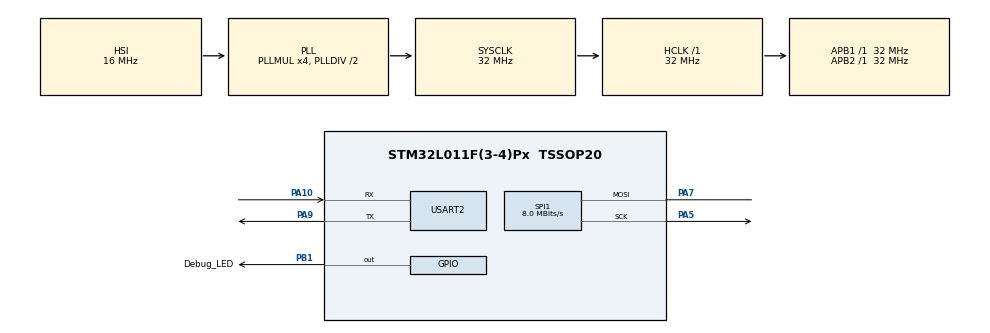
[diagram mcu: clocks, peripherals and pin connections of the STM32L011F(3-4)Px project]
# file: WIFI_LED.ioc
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Dma.Request0=SPI1_TX
Dma.SPI1_TX.0.Direction=DMA_MEMORY_TO_PERIPH
Dma.SPI1_TX.0.Instance=DMA1_Channel5
Dma.SPI1_TX.0.MemDataAlignment=DMA_MDATAALIGN_HALFWORD
Dma.SPI1_TX.0.MemInc=DMA_MINC_ENABLE
Dma.SPI1_TX.0.Mode=DMA_NORMAL
Dma.SPI1_TX.0.PeriphDataAlignment=DMA_PDATAALIGN_HALFWORD
Dma.SPI1_TX.0.PeriphInc=DMA_PINC_DISABLE
Dma.SPI1_TX.0.Priority=DMA_PRIORITY_HIGH
Mcu.Family=STM32L0
Mcu.Name=STM32L011F(3-4)Px
Mcu.Package=TSSOP20
NVIC.DMA1_Channel4_5_IRQn=true\:0\:0\:false\:false\:true\:false\:true
NVIC.USART2_IRQn=true\:0\:0\:false\:false\:true\:true\:true
PA10.Mode=Asynchronous
PA10.Signal=USART2_RX
PA13.Mode=Serial_Wire
PA13.Signal=SYS_SWDIO
PA14.Mode=Serial_Wire
PA14.Signal=SYS_SWCLK
PA5.Mode=Simplex_Bidirectional_Master
PA5.Signal=SPI1_SCK
PA7.Mode=Simplex_Bidirectional_Master
PA7.Signal=SPI1_MOSI
PA9.Mode=Asynchronous
PA9.Signal=USART2_TX
PB1.GPIO_Label=Debug_LED
PB1.GPIO_ModeDefaultOutputPP=GPIO_MODE_OUTPUT_PP
PB1.GPIO_PuPd=GPIO_PULLUP
PB1.GPIO_Speed=GPIO_SPEED_FREQ_LOW
PB1.PinState=GPIO_PIN_SET
PB1.Signal=GPIO_Output
PC14-OSC32_IN.Mode=LSE-External-Oscillator
PC14-OSC32_IN.Signal=RCC_OSC32_IN
PC15-OSC32_OUT.Mode=LSE-External-Oscillator
PC15-OSC32_OUT.Signal=RCC_OSC32_OUT
ProjectManager.HeapSize=0x200
ProjectManager.StackSize=0x400
ProjectManager.TargetToolchain=MDK-ARM V5.27
RCC.ADCFreq_Value=16000000
RCC.AHBFreq_Value=32000000
RCC.APB1Freq_Value=32000000
RCC.APB1TimFreq_Value=32000000
RCC.APB2Freq_Value=32000000
RCC.APB2TimFreq_Value=32000000
RCC.HCLKFreq_Value=32000000
RCC.HSE_VALUE=8000000
RCC.HSI16_VALUE=16000000
RCC.HSICalibrationValue=8
RCC.HSI_VALUE=16000000
RCC.MSI_VALUE=2097000
RCC.PLLMUL=RCC_PLLMUL_4
RCC.PREFETCH_ENABLE=1
RCC.SYSCLKFreq_VALUE=32000000
RCC.SYSCLKSource=RCC_SYSCLKSOURCE_PLLCLK
RCC.VCOOutputFreq_Value=64000000
SPI1.BaudRatePrescaler=SPI_BAUDRATEPRESCALER_4
SPI1.CalculateBaudRate=8.0 MBits/s
SPI1.DataSize=SPI_DATASIZE_16BIT
SPI1.Direction=SPI_DIRECTION_1LINE
SPI1.Mode=SPI_MODE_MASTER
SPI1.VirtualType=VM_MASTER
USART2.VirtualMode-Asynchronous=VM_ASYNC
board=custom

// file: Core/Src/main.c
/* USER CODE BEGIN Header */
/**
  ******************************************************************************
  * @file           : main.c
  * @brief          : Main program body
  ******************************************************************************
  * @attention
  *
  * <h2><center>&copy; Copyright (c) 2020 STMicroelectronics.
  * All rights reserved.</center></h2>
  *
  * This software component is licensed by ST under BSD 3-Clause license,
  * the "License"; You may not use this file except in compliance with the
  * License. You may obtain a copy of the License at:
  *                        opensource.org/licenses/BSD-3-Clause
  *
  ******************************************************************************
  */
/* USER CODE END Header */
#include "main.h"
#include "dma.h"
#include "spi.h"
#include "usart.h"
#include "gpio.h"

/* USER CODE BEGIN Includes */
#include "ApplicationMain.h"
/* USER CODE END Includes */

void SystemClock_Config(void);

int main(void)
{

  /* MCU Configuration--------------------------------------------------------*/

  /* Reset of all peripherals, Initializes the Flash interface and the Systick. */
  HAL_Init();

  /* Configure the system clock */
  SystemClock_Config();

  /* Initialize all configured peripherals */
  MX_GPIO_Init();
  MX_DMA_Init();
  MX_SPI1_Init();
  MX_USART2_UART_Init();
  /* USER CODE BEGIN 2 */
	ApplicationMain_Init();
  /* USER CODE END 2 */

  /* Infinite loop */
  /* USER CODE BEGIN WHILE */
  while (1)
  {
	  ApplicationMain_Loop();
    /* USER CODE END WHILE */

  }
}

void SystemClock_Config(void)
{
  RCC_OscInitTypeDef RCC_OscInitStruct = {0};
  RCC_ClkInitTypeDef RCC_ClkInitStruct = {0};
  RCC_PeriphCLKInitTypeDef PeriphClkInit = {0};

  /** Configure the main internal regulator output voltage
  */
  __HAL_PWR_VOLTAGESCALING_CONFIG(PWR_REGULATOR_VOLTAGE_SCALE1);
  /** Initializes the RCC Oscillators according to the specified parameters
  * in the RCC_OscInitTypeDef structure.
  */
  RCC_OscInitStruct.OscillatorType = RCC_OSCILLATORTYPE_HSI;
  RCC_OscInitStruct.HSIState = RCC_HSI_ON;
  RCC_OscInitStruct.HSICalibrationValue = 8;
  RCC_OscInitStruct.PLL.PLLState = RCC_PLL_ON;
  RCC_OscInitStruct.PLL.PLLSource = RCC_PLLSOURCE_HSI;
  RCC_OscInitStruct.PLL.PLLMUL = RCC_PLLMUL_4;
  RCC_OscInitStruct.PLL.PLLDIV = RCC_PLLDIV_2;
  if (HAL_RCC_OscConfig(&RCC_OscInitStruct) != HAL_OK)
  {
    Error_Handler();
  }
  /** Initializes the CPU, AHB and APB buses clocks
  */
  RCC_ClkInitStruct.ClockType = RCC_CLOCKTYPE_HCLK|RCC_CLOCKTYPE_SYSCLK
                              |RCC_CLOCKTYPE_PCLK1|RCC_CLOCKTYPE_PCLK2;
  RCC_ClkInitStruct.SYSCLKSource = RCC_SYSCLKSOURCE_PLLCLK;
  RCC_ClkInitStruct.AHBCLKDivider = RCC_SYSCLK_DIV1;
  RCC_ClkInitStruct.APB1CLKDivider = RCC_HCLK_DIV1;
  RCC_ClkInitStruct.APB2CLKDivider = RCC_HCLK_DIV1;

  if (HAL_RCC_ClockConfig(&RCC_ClkInitStruct, FLASH_LATENCY_1) != HAL_OK)
  {
    Error_Handler();
  }
  PeriphClkInit.PeriphClockSelection = RCC_PERIPHCLK_USART2;
  PeriphClkInit.Usart2ClockSelection = RCC_USART2CLKSOURCE_PCLK1;
  if (HAL_RCCEx_PeriphCLKConfig(&PeriphClkInit) != HAL_OK)
  {
    Error_Handler();
  }
}

void Error_Handler(void)
{
}

/************************ (C) COPYRIGHT STMicroelectronics *****END OF FILE****/
